# PIC32CM5112SG00048 register map
Vendor: Microchip Technology; Series: PIC32CMSG00; File version: 0
CPU: CM23 r0p0, little endian, MPU, no FPU, 2 interrupt priority bits, 141 interrupts, 13 SAU regions
Registers are 32-bit, read-write, reset 0x0 unless marked. A register's access mark holds for its fields unless they carry their own. Offsets are from the block's base; [hi:lo] are bit positions; lines under a group give offsets from that group; {n}, {i} and the like mark numbered series; 'fields as' and 'values as' point back to an identical list.

## AC — Analog Comparator Controller
Base 0x4482A000
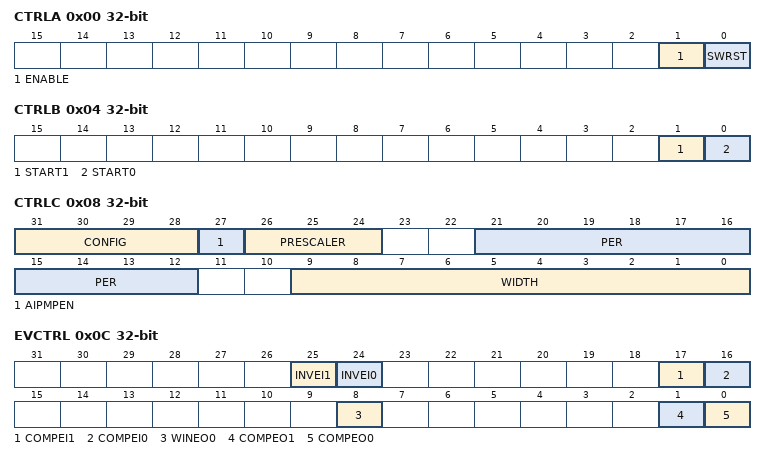
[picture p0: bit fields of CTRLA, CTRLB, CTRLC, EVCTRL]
0x00 CTRLA — Control A
  [1] ENABLE
  [0] SWRST — Software Reset
0x04 CTRLB — Control B
  [1] START1 — Comparator 1 Start Comparison
  [0] START0 — Comparator 0 Start Comparison
0x08 CTRLC — Control C
  [31:28] CONFIG — Configuration Extension
  [27] AIPMPEN — Analog Input Charge Pump Enable
  [26:24] PRESCALER — Prescaling Factor
    0=DIV1 (Sampling rate is GCLK_AC (No division)); 1=DIV2 (Sampling rate is GCLK_AC/2); 2=DIV4 (Sampling rate is GCLK_AC/4); 3=DIV8 (Sampling rate is GCLK_AC/8); 4=DIV16 (Sampling rate is GCLK_AC/16); 5=DIV32 (Sampling rate is GCLK_AC/32); 6=DIV64 (Sampling rate is GCLK_AC/64); 7=DIV128 (Sampling rate is GCLK_AC/128)
  [21:12] PER — Sample and Hold Clock Period
  [9:0] WIDTH — Sample and Hold Clock Pulse Width
0x0C EVCTRL — Event Control
  [25] INVEI1 — Inverted Event Input Enable 1
  [24] INVEI0 — Inverted Event Input Enable 0
  [17] COMPEI1 — Comparator 1 Event Input Enable
  [16] COMPEI0 — Comparator 0 Event Input Enable
  [8] WINEO0 — Window 0 Event Output Enable
  [1] COMPEO1 — Comparator 1 Event Output Enable
  [0] COMPEO0 — Comparator 0 Event Output Enable
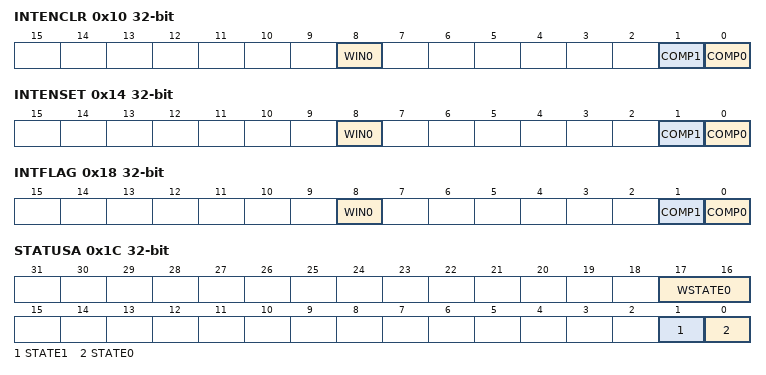
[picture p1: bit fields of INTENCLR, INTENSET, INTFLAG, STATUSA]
0x10 INTENCLR write-1-clears — Interrupt Enable Clear
  [8] WIN0 — Window 0 Interrupt Enable
  [1] COMP1 — Comparator 1 Interrupt Enable
  [0] COMP0 — Comparator 0 Interrupt Enable
0x14 INTENSET write-1-sets — Interrupt Enable Set
  fields as INTENCLR
0x18 INTFLAG write-1-clears — Interrupt Flag Status and Clear
  [8] WIN0 — Window 0
  [1] COMP1 — Comparator 1
  [0] COMP0 — Comparator 0
0x1C STATUSA ro
  [17:16] WSTATE0 — Window 0 Current State
    0=ABOVE (Signal is above window); 1=INSIDE (Signal is inside window); 2=BELOW (Signal is below window)
  [1] STATE1 — Comparator 1 Current State
  [0] STATE0 — Comparator 0 Current State
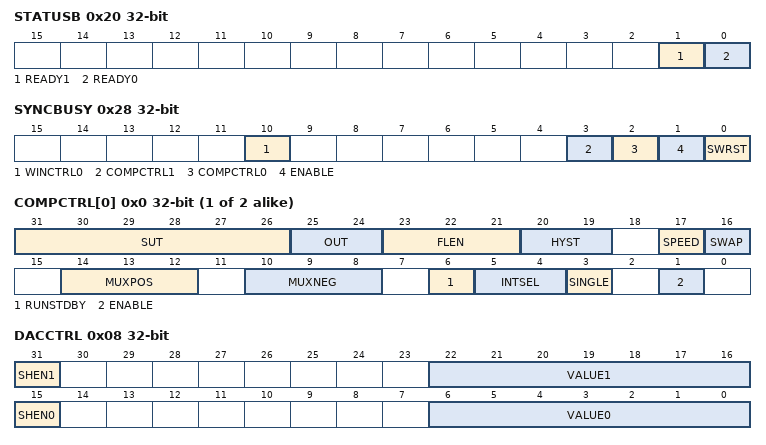
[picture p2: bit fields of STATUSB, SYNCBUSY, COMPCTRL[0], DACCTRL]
0x20 STATUSB ro
  [1] READY1 — Comparator 1 Ready
  [0] READY0 — Comparator 0 Ready
0x24 DBGCTRL — Debug Control
  [0] DBGRUN — Debug Run
0x28 SYNCBUSY ro — Synchronization Busy
  [10] WINCTRL0 — WINCTRL 0 Synchronization Busy
  [3] COMPCTRL1 — COMPCTRL 1 Synchronization Busy
  [2] COMPCTRL0 — COMPCTRL 0 Synchronization Busy
  [1] ENABLE — Enable Synchronization Busy
  [0] SWRST — Software Reset Synchronization Busy
{0x30+0x10*i} CHANNEL[{i}] (i=0..0) group
  {0x0+4j} COMPCTRL[{j}] (j=0..1) — Pair n Comparator Control 0
    [31:26] SUT — Start-up Time
    [25:24] OUT — Output
      0=OFF (The output of COMPn is not routed to the COMPn I/O port); 1=ASYNC (The asynchronous output of COMPn is routed to the COMPn I/O port); 2=SYNC (The synchronous output (including filtering) of COMPn is routed to the COMPn I/O port)
    [23:21] FLEN — Filter Length
      0=OFF (No filtering); 1=MAJ3 (3-bit majority function (2 of 3)); 2=MAJ5 (5-bit majority function (3 of 5))
    [20:19] HYST — Hysteresis Level
      0=10mV; 1=20mV; 2=40mV; 3=60mV
    [17] SPEED — Speed Selection
      0=HIGH (High speed, high power); 1=LOW (Low speed, low power)
    [16] SWAP — Swap Inputs and Invert
    [14:12] MUXPOS — Positive Input Mux Selection
      {v}=PIN{v} (I/O pin {v}) (v=0..3); 4=INT0 (Internal connection 0, device specific); 5=INT1 (Internal connection 1, device specific); 6=INT2 (Internal connection 2, device specific); 7=INTDAC (Internal DAC)
    [10:8] MUXNEG — Negative Input Mux Selection
      {v}=PIN{v} (I/O pin {v}) (v=0..3); 4=INT0 (Internal connection 0, device specific); 5=BANDGAP (Bangap); 6=GND (Ground); 7=INTDAC (Internal DAC)
    [6] RUNSTDBY — Run in Standby
    [5:4] INTSEL — Interrupt Selection
      0=TOGGLE (Interrupt on comparator output toggle); 1=RISING (Interrupt on comparator output rising); 2=FALLING (Interrupt on comparator output falling); 3=EOC (Interrupt on end of comparison (single-shot mode only))
    [3] SINGLE — Single-Shot Mode
    [1] ENABLE
  0x08 DACCTRL — Dac n Control
    [31] SHEN1 — DAC1 Sample and Hold Enable Operating Mode
    [22:16] VALUE1 — DAC1 Output Value
    [15] SHEN0 — DAC0 Sample and Hold Enable Operating Mode
    [6:0] VALUE0 — DAC0 Output Value
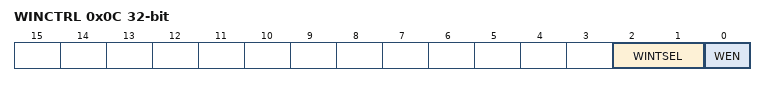
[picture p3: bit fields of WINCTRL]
  0x0C WINCTRL — Window Monitor n Control
    [2:1] WINTSEL — Window n Interrupt Selection
      0=ABOVE (Interrupt on signal above window); 1=INSIDE (Interrupt on signal inside window); 2=BELOW (Interrupt on signal below window); 3=OUTSIDE (Interrupt on signal outside window)
    [0] WEN — Window n Mode Enable

## Notices in the file
Copyright (c) 2026 Microchip Technology Inc.
SPDX-License-Identifier: Apache-2.0
Licensed under the Apache License, Version 2.0 (the "License");
you may not use this file except in compliance with the License.
You may obtain a copy of the License at
http://www.apache.org/licenses/LICENSE-2.0
Unless required by applicable law or agreed to in writing, software
distributed under the License is distributed on an "AS IS" BASIS,
WITHOUT WARRANTIES OR CONDITIONS OF ANY KIND, either express or implied.
See the License for the specific language governing permissions and
limitations under the License.
